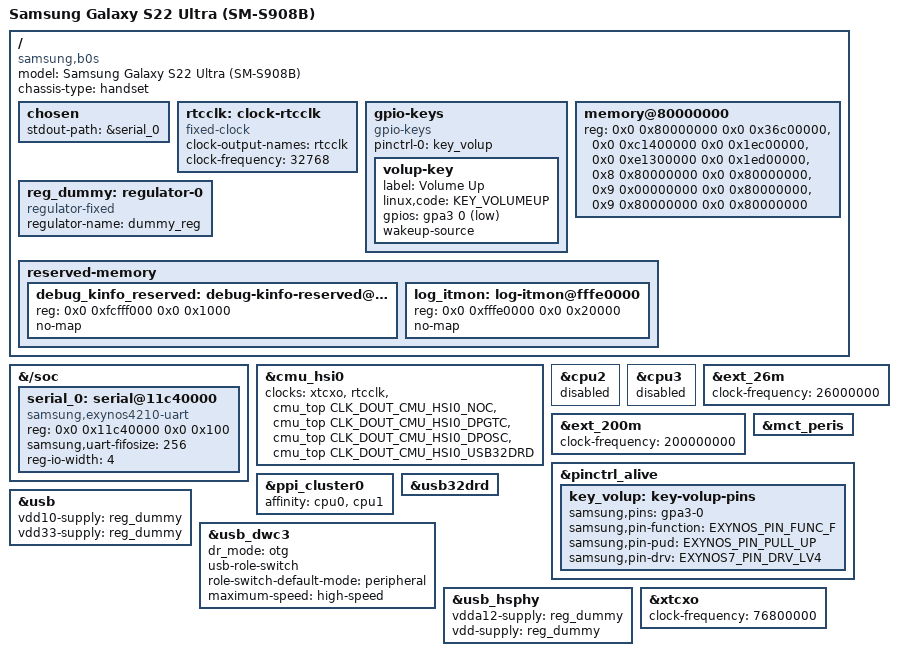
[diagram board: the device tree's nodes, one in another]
// SPDX-License-Identifier: GPL-2.0 OR BSD-3-Clause
/*
 * Samsung Galaxy S22 Ultra (b0s/SM-S908B) device tree source
 *
 * Derived from exynos2200-g0s.dts (Ivaylo Ivanov, 2025).
 *
 * EVERY b0s-specific value below was read off the LIVE device's
 * /proc/device-tree on 2026-09-24, not copied from g0s and not guessed:
 *
 *   model                 "Samsung B0S board based on S5E9925"
 *   memory banks          six, exact reg values from the live DT
 *   debug UART            uart@11C40000 - the ONLY node carrying
 *                         samsung,dbg-uart-baud / dbg-uart-ch / dbg-word-len,
 *                         and one of only two with status = "okay"
 *   fifo size             samsung,fifo-size = 0x100 = 256
 *   baud                  samsung,dbg-uart-baud = 0x1c200 = 115200
 *   word length           samsung,dbg-word-len = 8
 *   reg-io-width          4
 *   panel                 1440x3088 (from /sys/class/drm/../modes)
 */

/dts-v1/;
#include "exynos2200.dtsi"
#include <dt-bindings/gpio/gpio.h>
#include <dt-bindings/input/input.h>
#include <dt-bindings/interrupt-controller/irq.h>

/ {
	model = "Samsung Galaxy S22 Ultra (SM-S908B)";
	compatible = "samsung,b0s", "samsung,exynos2200";
	chassis-type = "handset";

	chosen {
		#address-cells = <2>;
		#size-cells = <2>;
		ranges;

		stdout-path = &serial_0;

		/*
		 * NO simple-framebuffer node, deliberately.
		 *
		 * g0s reserves 1080*2340*4 at 0xf6200000. b0s boots the same
		 * base (s3cfb.bootloaderfb=0xf6200000 in the stock cmdline)
		 * but its panel is 1440x3088, and the bootloader's splash
		 * geometry is NOT derivable from this device: there is no
		 * reserved-memory node at 0xf6200000 in the live DT and no
		 * fb0 sysfs node. Declaring a wrong width/height/stride would
		 * have the kernel scribble outside the real buffer.
		 *
		 * Console here is the UART, which IS verified. Add simplefb
		 * only once the real geometry is read from the bootloader.
		 */
	};

	/*
	 * RTC clock (XrtcXTI); external, must be 32.768 kHz.
	 * TODO: remove once RTC is implemented as part of the PMIC driver.
	 */
	rtcclk: clock-rtcclk {
		compatible = "fixed-clock";
		clock-output-names = "rtcclk";
		#clock-cells = <0>;
		clock-frequency = <32768>;
	};

	gpio-keys {
		compatible = "gpio-keys";

		pinctrl-0 = <&key_volup>;
		pinctrl-names = "default";

		volup-key {
			label = "Volume Up";
			linux,code = <KEY_VOLUMEUP>;
			gpios = <&gpa3 0 GPIO_ACTIVE_LOW>;
			wakeup-source;
		};
	};

	/*
	 * Six banks, verbatim from the live DT. g0s merges its upper banks
	 * into one entry; b0s is NOT merged here because the lower region is
	 * genuinely fragmented (0x80000000, 0xc1400000, 0xe1300000) and
	 * inventing a contiguous range would hand the kernel memory that the
	 * carveouts actually own.
	 */
	memory@80000000 {
		device_type = "memory";
		reg = <0x0 0x80000000  0x0 0x36c00000>,
		      <0x0 0xc1400000  0x0 0x1ec00000>,
		      <0x0 0xe1300000  0x0 0x1ed00000>,
		      <0x8 0x80000000  0x0 0x80000000>,
		      <0x9 0x00000000  0x0 0x80000000>,
		      <0x9 0x80000000  0x0 0x80000000>;
	};

	/* TODO: remove once PMIC is implemented */
	reg_dummy: regulator-0 {
		compatible = "regulator-fixed";
		regulator-name = "dummy_reg";
	};

	reserved-memory {
		#address-cells = <2>;
		#size-cells = <2>;
		ranges;

		debug_kinfo_reserved: debug-kinfo-reserved@fcfff000 {
			reg = <0x0 0xfcfff000 0x0 0x1000>;
			no-map;
		};

		log_itmon: log-itmon@fffe0000 {
			reg = <0x0 0xfffe0000 0x0 0x20000>;
			no-map;
		};
	};
};

/*
 * The debug UART.
 *
 * exynos2200.dtsi upstream contains NO uart/serial node at all - that is the
 * root cause of the "A1 is console-silent" finding, and it is a SoC-level
 * omission, not a board one. The node goes into /soc, which is an unlabelled
 * simple-bus with #address-cells = <2>, #size-cells = <2>.
 *
 * Deliberately minimal: no clocks, no pinctrl. SBOOT has already configured
 * and enabled this UART before the kernel runs, and earlycon is polled MMIO,
 * so it produces output without any clock driver. mainline exynos2200 has no
 * peric CMU node yet, so a clocks property here could only point at something
 * that does not exist.
 *
 * Pair with:  earlycon=exynos4210,0x11c40000 keep_bootcon console=ttySAC0,115200
 * keep_bootcon matters: if the full ttySAC0 probe fails for want of a clock,
 * the boot console stays alive and you still see the failure.
 */
&{/soc} {
	serial_0: serial@11c40000 {
		compatible = "samsung,exynos4210-uart";
		reg = <0x0 0x11c40000 0x0 0x100>;
		samsung,uart-fifosize = <256>;
		reg-io-width = <4>;
		status = "okay";
	};
};

&cmu_hsi0 {
	clocks = <&xtcxo>,
		 <&rtcclk>,
		 <&cmu_top CLK_DOUT_CMU_HSI0_NOC>,
		 <&cmu_top CLK_DOUT_CMU_HSI0_DPGTC>,
		 <&cmu_top CLK_DOUT_CMU_HSI0_DPOSC>,
		 <&cmu_top CLK_DOUT_CMU_HSI0_USB32DRD>;
	clock-names = "oscclk", "rtcclk", "noc", "dpgtc", "dposc", "usb";
};

/*
 * Inherited from g0s: cpu2/cpu3 fail to come up consistently and hang the
 * boot later. Kept because it is an exynos2200 issue, not a g0s one, and a
 * first b0s boot should not also be debugging SMP. Revisit with nr_cpus=1
 * once there is a console.
 */
&cpu2 {
	status = "fail";
};

&cpu3 {
	status = "fail";
};

&ext_26m {
	clock-frequency = <26000000>;
};

&ext_200m {
	clock-frequency = <200000000>;
};

&mct_peris {
	status = "okay";
};

&pinctrl_alive {
	key_volup: key-volup-pins {
		samsung,pins = "gpa3-0";
		samsung,pin-function = <EXYNOS_PIN_FUNC_F>;
		samsung,pin-pud = <EXYNOS_PIN_PULL_UP>;
		samsung,pin-drv = <EXYNOS7_PIN_DRV_LV4>;
	};
};

&ppi_cluster0 {
	affinity = <&cpu0 &cpu1>;
};

&usb {
	/* TODO: replace once PMIC is implemented */
	vdd10-supply = <&reg_dummy>;
	vdd33-supply = <&reg_dummy>;
	status = "okay";
};

&usb32drd {
	status = "okay";
};

&usb_dwc3 {
	dr_mode = "otg";
	usb-role-switch;
	role-switch-default-mode = "peripheral";
	maximum-speed = "high-speed";
};

&usb_hsphy {
	/* TODO: replace once PMIC is implemented */
	vdda12-supply = <&reg_dummy>;
	vdd-supply = <&reg_dummy>;
	status = "okay";
};

&xtcxo {
	clock-frequency = <76800000>;
};
